# Radio Core register map
Vendor: Andy Lee; Series: Fishball; File version: 2.1.0
Fishball radio core: lanes, spectrum, capture, 8-VSB (platform 0)
Registers are 32-bit, read-write, no defined reset value unless marked. A register's access mark holds for its fields unless they carry their own. Offsets are from the block's base; lines under a group give offsets from that group; [hi:lo] are bit positions; {n}, {i} and the like mark numbered series; 'fields as' and 'values as' point back to an identical list; <NAME> marks a mode.

## Memory map
0x00000000 Radio_Core size 0x160 — Fishball radio core: lanes, spectrum, capture, 8-VSB (platform 0)

## Radio_Core — Fishball radio core: lanes, spectrum, capture, 8-VSB (platform 0)
Base 0x00000000
0x00 product_id ro
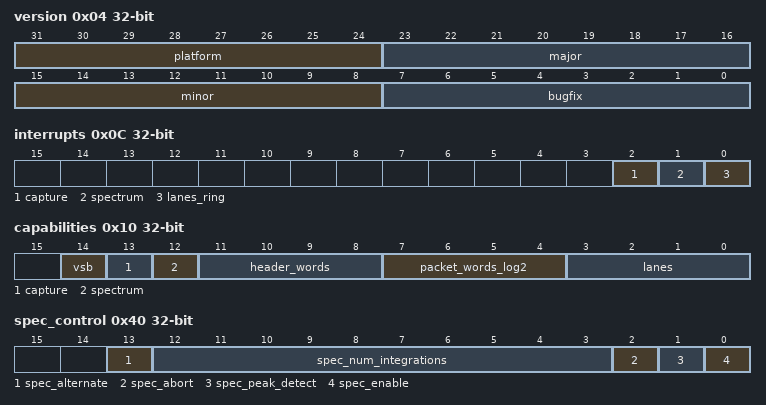
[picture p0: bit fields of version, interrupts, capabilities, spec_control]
0x04 version ro
  [31:24] platform, [23:16] major, [15:8] minor, [7:0] bugfix
0x08 control
  [0] sdr_reset
0x0C interrupts ro
  [2] capture, [1] spectrum, [0] lanes_ring
0x10 capabilities ro
  [14] vsb, [13] capture, [12] spectrum, [11:8] header_words, [7:4] packet_words_log2, [3:0] lanes
0x20 lanes_ring_control
  [0] enable
0x24 lanes_ring_status ro
  [8:0] last_buffer
0x28 lanes_ring_next_address ro
  [31:0] next_address
0x2C sample_count_lo ro
  [31:0] count
0x30 sample_count_hi ro
  [31:0] count
0x34 adc_clips ro
  [31:0] count
0x40 spec_control
  [13] spec_alternate, [12:3] spec_num_integrations, [2] spec_abort wo, [1] spec_peak_detect, [0] spec_enable
0x44 spec_status ro
  [3:0] spec_last_buffer
0x48 spec_next_address ro
  [31:0] next_address
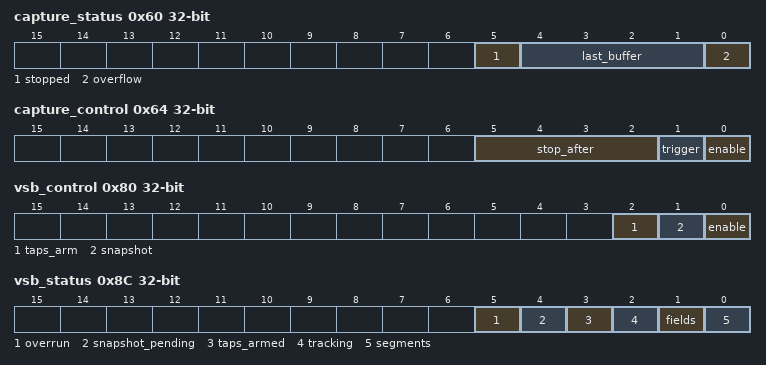
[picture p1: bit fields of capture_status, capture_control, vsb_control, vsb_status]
0x60 capture_status ro
  [5] stopped, [4:1] last_buffer, [0] overflow
0x64 capture_control
  [5:2] stop_after, [1] trigger wo, [0] enable
0x68 capture_next_address ro
  [31:0] next_address
0x6C capture_start_lo ro
  [31:0] index
0x70 capture_start_hi ro
  [31:0] index
0x74 capture_buffers ro
  [31:0] count
0x80 vsb_control
  [2] taps_arm wo, [1] snapshot wo, [0] enable
0x84 vsb_step
0x88 vsb_carrier
  [31:0] frequency
0x8C vsb_status ro
  [5] overrun, [4] snapshot_pending, [3] taps_armed, [2] tracking, [1] fields, [0] segments
0x90 vsb_taps_loaded ro
  [15:0] count
0x94 vsb_fields ro
  [31:0] count
0x98 vsb_lost ro
  [31:0] count
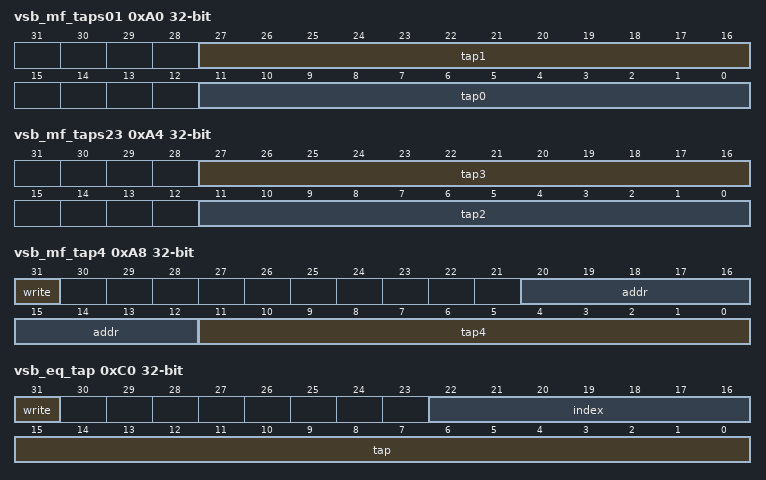
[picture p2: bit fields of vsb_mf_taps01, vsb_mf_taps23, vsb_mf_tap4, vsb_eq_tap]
0xA0 vsb_mf_taps01
  [27:16] tap1, [11:0] tap0
0xA4 vsb_mf_taps23
  [27:16] tap3, [11:0] tap2
0xA8 vsb_mf_tap4
  [31] write wo, [20:12] addr, [11:0] tap4
0xC0 vsb_eq_tap
  [31] write wo, [22:16] index, [15:0] tap
{0x100+0x20*i} lane{i}_ddc_coeff_addr (i=0..2)
  [9:0] coeff_waddr
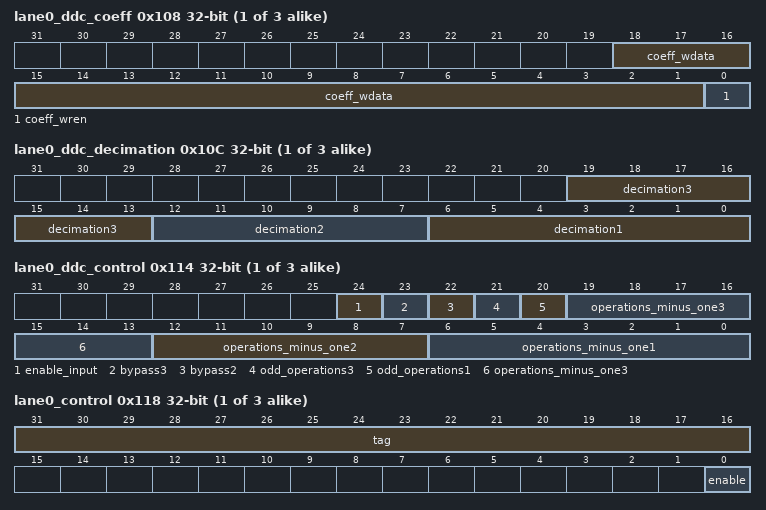
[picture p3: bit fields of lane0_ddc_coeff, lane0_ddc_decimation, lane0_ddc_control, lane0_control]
{0x108+0x20*i} lane{i}_ddc_coeff (i=0..2)
  [18:1] coeff_wdata, [0] coeff_wren wo
{0x10C+0x20*i} lane{i}_ddc_decimation (i=0..2)
  [19:13] decimation3, [12:7] decimation2, [6:0] decimation1
{0x110+0x20*i} lane{i}_ddc_frequency (i=0..2)
  [27:0] frequency
{0x114+0x20*i} lane{i}_ddc_control (i=0..2)
  [24] enable_input, [23] bypass3, [22] bypass2, [21] odd_operations3, [20] odd_operations1, [19:13] operations_minus_one3, [12:7] operations_minus_one2, [6:0] operations_minus_one1
{0x118+0x20*i} lane{i}_control (i=0..2)
  [31:16] tag, [0] enable
{0x11C+0x20*i} lane{i}_status ro (i=0..2)
  [0] lost

## Licence text in the file
SPDX-License-Identifier: MIT
